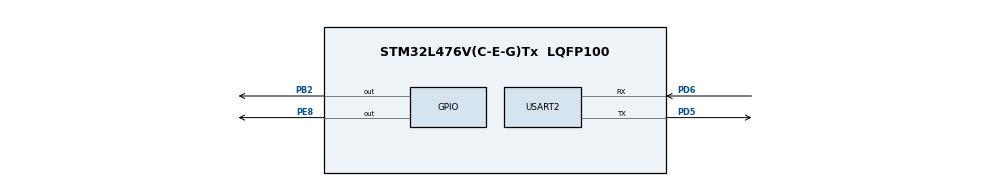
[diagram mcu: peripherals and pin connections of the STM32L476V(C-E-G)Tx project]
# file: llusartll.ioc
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Dma.Request0=USART2_TX
Dma.Request1=USART2_RX
Dma.USART2_RX.1.Direction=DMA_PERIPH_TO_MEMORY
Dma.USART2_RX.1.Instance=DMA1_Channel6
Dma.USART2_RX.1.MemDataAlignment=DMA_MDATAALIGN_BYTE
Dma.USART2_RX.1.MemInc=DMA_MINC_ENABLE
Dma.USART2_RX.1.Mode=DMA_NORMAL
Dma.USART2_RX.1.PeriphDataAlignment=DMA_PDATAALIGN_BYTE
Dma.USART2_RX.1.PeriphInc=DMA_PINC_DISABLE
Dma.USART2_RX.1.Priority=DMA_PRIORITY_LOW
Dma.USART2_TX.0.Direction=DMA_MEMORY_TO_PERIPH
Dma.USART2_TX.0.Instance=DMA1_Channel7
Dma.USART2_TX.0.MemDataAlignment=DMA_MDATAALIGN_BYTE
Dma.USART2_TX.0.MemInc=DMA_MINC_ENABLE
Dma.USART2_TX.0.Mode=DMA_NORMAL
Dma.USART2_TX.0.PeriphDataAlignment=DMA_PDATAALIGN_BYTE
Dma.USART2_TX.0.PeriphInc=DMA_PINC_DISABLE
Dma.USART2_TX.0.Priority=DMA_PRIORITY_LOW
Mcu.Family=STM32L4
Mcu.Name=STM32L476V(C-E-G)Tx
Mcu.Package=LQFP100
NVIC.DMA1_Channel6_IRQn=true\:0\:0\:false\:false\:true\:false\:true\:true
NVIC.DMA1_Channel7_IRQn=true\:0\:0\:false\:false\:true\:false\:true\:true
NVIC.PriorityGroup=NVIC_PRIORITYGROUP_4
NVIC.USART2_IRQn=true\:0\:0\:false\:false\:true\:true\:true\:true
PB2.Signal=GPIO_Output
PD5.Mode=Asynchronous
PD5.Signal=USART2_TX
PD6.Mode=Asynchronous
PD6.Signal=USART2_RX
PE8.Signal=GPIO_Output
ProjectManager.HeapSize=0x200
ProjectManager.StackSize=0x400
ProjectManager.TargetToolchain=EWARM V7
RCC.HSE_VALUE=8000000
RCC.HSI_VALUE=16000000
RCC.LSE_VALUE=32768
RCC.MSI_VALUE=4000000
RCC.VCOOutputFreq_Value=32000000
USART2.VirtualMode-Asynchronous=VM_ASYNC
board=custom

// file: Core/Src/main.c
/* USER CODE BEGIN Header */
/**
  ******************************************************************************
  * @file           : main.c
  * @brief          : Main program body
  ******************************************************************************
  * @attention
  *
  * Copyright (c) 2025 STMicroelectronics.
  * All rights reserved.
  *
  * This software is licensed under terms that can be found in the LICENSE file
  * in the root directory of this software component.
  * If no LICENSE file comes with this software, it is provided AS-IS.
  *
  ******************************************************************************
  */
/* USER CODE END Header */
#include "main.h"

void SystemClock_Config(void);
static void MX_GPIO_Init(void);
static void MX_DMA_Init(void);
static void MX_USART2_UART_Init(void);

/* USER CODE BEGIN 0 */
#define _CR 0x0d
#define _LF 0x0a

uint8_t buffer[] = "Data received.\r\n";
int recvComplete;

void DMA_TransmitData();

void DMA_TransmitData()
{

  LL_DMA_DisableIT_TE(DMA1, LL_DMA_CHANNEL_6);

  LL_DMA_SetDataLength(DMA1, LL_DMA_CHANNEL_6, sizeof(buffer));

  LL_DMA_EnableIT_TE(DMA1, LL_DMA_CHANNEL_6);

  LL_USART_EnableDMAReq_TX(USART2);
}
/* USER CODE END 0 */

int main(void)
{

  /* MCU Configuration--------------------------------------------------------*/

  /* Reset of all peripherals, Initializes the Flash interface and the Systick. */
  HAL_Init();

  /* Configure the system clock */
  SystemClock_Config();

  /* Initialize all configured peripherals */
  MX_GPIO_Init();
  MX_DMA_Init();
  MX_USART2_UART_Init();
  LL_DMA_EnableIT_TC(DMA1, LL_DMA_CHANNEL_6);
LL_USART_EnableIT_RXNE(USART2);

  /* Infinite loop */
  while (1)
  {
if (recvComplete)
  {
    recvComplete = 0;
    DMA_TransmitData();
  }
  }
}

void SystemClock_Config(void)
{
  LL_FLASH_SetLatency(LL_FLASH_LATENCY_0);
  while(LL_FLASH_GetLatency()!= LL_FLASH_LATENCY_0)
  {
  }
  LL_PWR_SetRegulVoltageScaling(LL_PWR_REGU_VOLTAGE_SCALE1);
  while (LL_PWR_IsActiveFlag_VOS() != 0)
  {
  }
  LL_RCC_MSI_Enable();

   /* Wait till MSI is ready */
  while(LL_RCC_MSI_IsReady() != 1)
  {

  }
  LL_RCC_MSI_EnableRangeSelection();
  LL_RCC_MSI_SetRange(LL_RCC_MSIRANGE_6);
  LL_RCC_MSI_SetCalibTrimming(0);
  LL_RCC_SetSysClkSource(LL_RCC_SYS_CLKSOURCE_MSI);

   /* Wait till System clock is ready */
  while(LL_RCC_GetSysClkSource() != LL_RCC_SYS_CLKSOURCE_STATUS_MSI)
  {

  }
  LL_RCC_SetAHBPrescaler(LL_RCC_SYSCLK_DIV_1);
  LL_RCC_SetAPB1Prescaler(LL_RCC_APB1_DIV_1);
  LL_RCC_SetAPB2Prescaler(LL_RCC_APB2_DIV_1);
  LL_SetSystemCoreClock(4000000);

   /* Update the time base */
  if (HAL_InitTick (TICK_INT_PRIORITY) != HAL_OK)
  {
    Error_Handler();
  }
}

static void MX_USART2_UART_Init(void)
{

  LL_USART_InitTypeDef USART_InitStruct = {0};

  LL_GPIO_InitTypeDef GPIO_InitStruct = {0};

  LL_RCC_SetUSARTClockSource(LL_RCC_USART2_CLKSOURCE_PCLK1);

  /* Peripheral clock enable */
  LL_APB1_GRP1_EnableClock(LL_APB1_GRP1_PERIPH_USART2);

  LL_AHB2_GRP1_EnableClock(LL_AHB2_GRP1_PERIPH_GPIOD);
  /**USART2 GPIO Configuration
  PD5   ------> USART2_TX
  PD6   ------> USART2_RX
  */
  GPIO_InitStruct.Pin = LL_GPIO_PIN_5|LL_GPIO_PIN_6;
  GPIO_InitStruct.Mode = LL_GPIO_MODE_ALTERNATE;
  GPIO_InitStruct.Speed = LL_GPIO_SPEED_FREQ_VERY_HIGH;
  GPIO_InitStruct.OutputType = LL_GPIO_OUTPUT_PUSHPULL;
  GPIO_InitStruct.Pull = LL_GPIO_PULL_NO;
  GPIO_InitStruct.Alternate = LL_GPIO_AF_7;
  LL_GPIO_Init(GPIOD, &GPIO_InitStruct);

  /* USART2 DMA Init */

  /* USART2_TX Init */
  LL_DMA_SetPeriphRequest(DMA1, LL_DMA_CHANNEL_7, LL_DMA_REQUEST_2);

  LL_DMA_SetDataTransferDirection(DMA1, LL_DMA_CHANNEL_7, LL_DMA_DIRECTION_MEMORY_TO_PERIPH);

  LL_DMA_SetChannelPriorityLevel(DMA1, LL_DMA_CHANNEL_7, LL_DMA_PRIORITY_LOW);

  LL_DMA_SetMode(DMA1, LL_DMA_CHANNEL_7, LL_DMA_MODE_NORMAL);

  LL_DMA_SetPeriphIncMode(DMA1, LL_DMA_CHANNEL_7, LL_DMA_PERIPH_NOINCREMENT);

  LL_DMA_SetMemoryIncMode(DMA1, LL_DMA_CHANNEL_7, LL_DMA_MEMORY_INCREMENT);

  LL_DMA_SetPeriphSize(DMA1, LL_DMA_CHANNEL_7, LL_DMA_PDATAALIGN_BYTE);

  LL_DMA_SetMemorySize(DMA1, LL_DMA_CHANNEL_7, LL_DMA_MDATAALIGN_BYTE);

  /* USART2_RX Init */
  LL_DMA_SetPeriphRequest(DMA1, LL_DMA_CHANNEL_6, LL_DMA_REQUEST_2);

  LL_DMA_SetDataTransferDirection(DMA1, LL_DMA_CHANNEL_6, LL_DMA_DIRECTION_PERIPH_TO_MEMORY);

  LL_DMA_SetChannelPriorityLevel(DMA1, LL_DMA_CHANNEL_6, LL_DMA_PRIORITY_LOW);

  LL_DMA_SetMode(DMA1, LL_DMA_CHANNEL_6, LL_DMA_MODE_NORMAL);

  LL_DMA_SetPeriphIncMode(DMA1, LL_DMA_CHANNEL_6, LL_DMA_PERIPH_NOINCREMENT);

  LL_DMA_SetMemoryIncMode(DMA1, LL_DMA_CHANNEL_6, LL_DMA_MEMORY_INCREMENT);

  LL_DMA_SetPeriphSize(DMA1, LL_DMA_CHANNEL_6, LL_DMA_PDATAALIGN_BYTE);

  LL_DMA_SetMemorySize(DMA1, LL_DMA_CHANNEL_6, LL_DMA_MDATAALIGN_BYTE);

  /* USART2 interrupt Init */
  NVIC_SetPriority(USART2_IRQn, NVIC_EncodePriority(NVIC_GetPriorityGrouping(),0, 0));
  NVIC_EnableIRQ(USART2_IRQn);

  USART_InitStruct.BaudRate = 115200;
  USART_InitStruct.DataWidth = LL_USART_DATAWIDTH_8B;
  USART_InitStruct.StopBits = LL_USART_STOPBITS_1;
  USART_InitStruct.Parity = LL_USART_PARITY_NONE;
  USART_InitStruct.TransferDirection = LL_USART_DIRECTION_TX_RX;
  USART_InitStruct.HardwareFlowControl = LL_USART_HWCONTROL_NONE;
  USART_InitStruct.OverSampling = LL_USART_OVERSAMPLING_16;
  LL_USART_Init(USART2, &USART_InitStruct);
  LL_USART_ConfigAsyncMode(USART2);
  LL_USART_Enable(USART2);

}

static void MX_DMA_Init(void)
{

  /* DMA controller clock enable */
  __HAL_RCC_DMA1_CLK_ENABLE();

  /* DMA interrupt init */
  /* DMA1_Channel6_IRQn interrupt configuration */
  NVIC_SetPriority(DMA1_Channel6_IRQn, NVIC_EncodePriority(NVIC_GetPriorityGrouping(),0, 0));
  NVIC_EnableIRQ(DMA1_Channel6_IRQn);
  /* DMA1_Channel7_IRQn interrupt configuration */
  NVIC_SetPriority(DMA1_Channel7_IRQn, NVIC_EncodePriority(NVIC_GetPriorityGrouping(),0, 0));
  NVIC_EnableIRQ(DMA1_Channel7_IRQn);

}

static void MX_GPIO_Init(void)
{
  LL_GPIO_InitTypeDef GPIO_InitStruct = {0};

  /* GPIO Ports Clock Enable */
  LL_AHB2_GRP1_EnableClock(LL_AHB2_GRP1_PERIPH_GPIOB);
  LL_AHB2_GRP1_EnableClock(LL_AHB2_GRP1_PERIPH_GPIOE);
  LL_AHB2_GRP1_EnableClock(LL_AHB2_GRP1_PERIPH_GPIOD);

  /**/
  LL_GPIO_ResetOutputPin(GPIOB, LL_GPIO_PIN_2);

  /**/
  LL_GPIO_ResetOutputPin(GPIOE, LL_GPIO_PIN_8);

  /**/
  GPIO_InitStruct.Pin = LL_GPIO_PIN_2;
  GPIO_InitStruct.Mode = LL_GPIO_MODE_OUTPUT;
  GPIO_InitStruct.Speed = LL_GPIO_SPEED_FREQ_LOW;
  GPIO_InitStruct.OutputType = LL_GPIO_OUTPUT_PUSHPULL;
  GPIO_InitStruct.Pull = LL_GPIO_PULL_NO;
  LL_GPIO_Init(GPIOB, &GPIO_InitStruct);

  /**/
  GPIO_InitStruct.Pin = LL_GPIO_PIN_8;
  GPIO_InitStruct.Mode = LL_GPIO_MODE_OUTPUT;
  GPIO_InitStruct.Speed = LL_GPIO_SPEED_FREQ_LOW;
  GPIO_InitStruct.OutputType = LL_GPIO_OUTPUT_PUSHPULL;
  GPIO_InitStruct.Pull = LL_GPIO_PULL_NO;
  LL_GPIO_Init(GPIOE, &GPIO_InitStruct);

}

void Error_Handler(void)
{
  __disable_irq();
  while (1)
  {
  }
}
